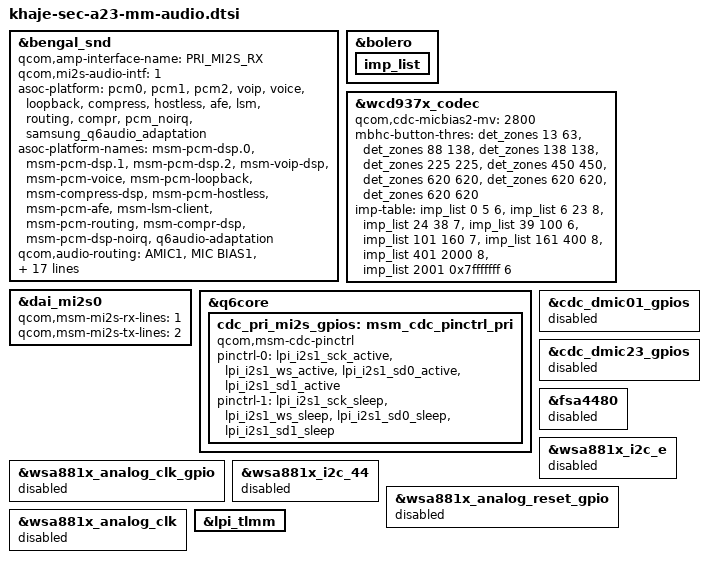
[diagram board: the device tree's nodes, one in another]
// SPDX-License-Identifier: GPL-2.0
/*
 * Galaxy A23 4G: audio nodes carried over from 4.19.
 * These target labels that the khaje base DTB (CLO 5.15) does not
 * define; they are provided by the separate Qualcomm display/audio/
 * camera devicetree repos. Built as their own dtbo, not merged into the
 * core DTB.
 */

/* from a23/khaje-sec.a23.08.dtsi */
&bengal_snd {
	qcom,amp-interface-name = "PRI_MI2S_RX";
};

/* from a23/khaje-sec.a23.09.dtsi */
&bengal_snd {
	qcom,amp-interface-name = "PRI_MI2S_RX";
};

/* from khaje-sec-a23-audio-common.dtsi */
&bolero {
	imp_list: imp_list {
		#list-imp-cells = <3>;
	};
};

/* from khaje-sec-a23-audio-common.dtsi */
&wcd937x_codec {
	qcom,cdc-micbias2-mv = <2800>;
	mbhc-button-thres = <&det_zones 13 63>,
		 <&det_zones 88 138>,
		 <&det_zones 138 138>,
		 <&det_zones 225 225>,
		 <&det_zones 450 450>,
		 <&det_zones 620 620>,
		 <&det_zones 620 620>,
		 <&det_zones 620 620>;
	imp-table = <&imp_list 0 5 6>,
			 <&imp_list 6 23 8>,
			 <&imp_list 24 38 7>,
			 <&imp_list 39 100 6>,
			 <&imp_list 101 160 7>,
			 <&imp_list 161 400 8>,
			 <&imp_list 401 2000 8>,
			 <&imp_list 2001 0x7fffffff 6>;
};

/* from khaje-sec-a23-audio-common.dtsi */
&bengal_snd {
	qcom,mi2s-audio-intf = <1>;
	asoc-platform = <&pcm0>, <&pcm1>, <&pcm2>, <&voip>, <&voice>,
			<&loopback>, <&compress>, <&hostless>,
			<&afe>, <&lsm>, <&routing>, <&compr>,
			<&pcm_noirq>, <&samsung_q6audio_adaptation>;
	asoc-platform-names = "msm-pcm-dsp.0", "msm-pcm-dsp.1",
			"msm-pcm-dsp.2", "msm-voip-dsp",
			"msm-pcm-voice", "msm-pcm-loopback",
			"msm-compress-dsp", "msm-pcm-hostless",
			"msm-pcm-afe", "msm-lsm-client",
			"msm-pcm-routing", "msm-compr-dsp",
			"msm-pcm-dsp-noirq", "q6audio-adaptation";
	qcom,audio-routing =
		"AMIC1", "MIC BIAS1",
		"MIC BIAS1", "Analog Mic1",
		"AMIC2", "MIC BIAS2",
		"MIC BIAS2", "Analog Mic2",
		"AMIC3", "MIC BIAS3",
		"MIC BIAS3", "Analog Mic3",
		"TX DMIC0", "MIC BIAS1",
		"IN1_HPHL", "HPHL_OUT",
		"IN2_HPHR", "HPHR_OUT",
		"TX SWR_MIC0", "ADC1_OUTPUT",
		"TX SWR_MIC4", "ADC2_OUTPUT",
		"TX SWR_MIC5", "ADC3_OUTPUT",
		"RX_TX DEC0_INP", "TX DEC0 MUX",
		"RX_TX DEC1_INP", "TX DEC1 MUX",
		"RX_TX DEC2_INP", "TX DEC2 MUX",
		"RX_TX DEC3_INP", "TX DEC3 MUX",
		"TX_AIF1 CAP", "VA_TX_SWR_CLK",
		"TX_AIF2 CAP", "VA_TX_SWR_CLK",
		"TX_AIF3 CAP", "VA_TX_SWR_CLK";
	qcom,cdc-dmic01-gpios = <>;
	qcom,cdc-dmic23-gpios = <>;
	qcom,wsa-max-devs = <0>;
	qcom,wsa-devs = <0>;
	qcom,pri-mi2s-gpios = <&cdc_pri_mi2s_gpios>;
	fsa4480-i2c-handle = <>;
};

/* from khaje-sec-a23-audio-common.dtsi */
&dai_mi2s0 {
	qcom,msm-mi2s-rx-lines = <1>;
	qcom,msm-mi2s-tx-lines = <2>;
};

/* from khaje-sec-a23-audio-common.dtsi */
&q6core {
	cdc_pri_mi2s_gpios: msm_cdc_pinctrl_pri {
		compatible = "qcom,msm-cdc-pinctrl";
		pinctrl-names = "aud_active", "aud_sleep";
		pinctrl-0 = <&lpi_i2s1_sck_active &lpi_i2s1_ws_active
			&lpi_i2s1_sd0_active &lpi_i2s1_sd1_active>;
		pinctrl-1 = <&lpi_i2s1_sck_sleep &lpi_i2s1_ws_sleep
			&lpi_i2s1_sd0_sleep &lpi_i2s1_sd1_sleep>;
	};
};

/* from khaje-sec-a23-audio-common.dtsi */
&cdc_dmic01_gpios {
	status = "disabled";
};

/* from khaje-sec-a23-audio-common.dtsi */
&cdc_dmic23_gpios {
	status = "disabled";
};

/* from khaje-sec-a23-audio-common.dtsi */
&wsa881x_analog_clk_gpio {
	status = "disabled";
};

/* from khaje-sec-a23-audio-common.dtsi */
&fsa4480 {
	status = "disabled";
};

/* from khaje-sec-a23-audio-common.dtsi */
&wsa881x_i2c_e {
	status = "disabled";
};

/* from khaje-sec-a23-audio-common.dtsi */
&wsa881x_i2c_44 {
	status = "disabled";
};

/* from khaje-sec-a23-audio-common.dtsi */
&wsa881x_analog_reset_gpio {
	status = "disabled";
};

/* from khaje-sec-a23-audio-common.dtsi */
&wsa881x_analog_clk {
	status = "disabled";
};

/* from khaje-sec-a23-audio-pinctrl-common.dtsi */
&lpi_tlmm {

};
